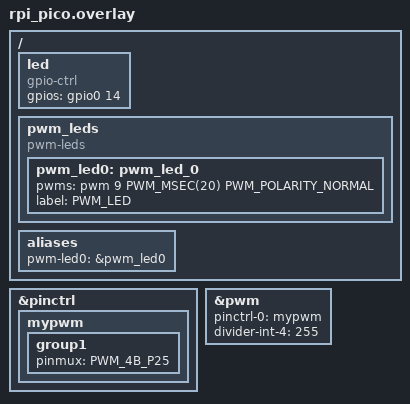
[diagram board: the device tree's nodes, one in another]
/ {
    led: led {
        compatible = "gpio-ctrl";
        gpios = <&gpio0 14 0x0>;
    };

	pwm_leds {
		compatible = "pwm-leds";
		status = "okay";
		pwm_led0: pwm_led_0 {
			pwms = <&pwm 9 PWM_MSEC(20) PWM_POLARITY_NORMAL>;
			label = "PWM_LED";
		};
	};

	aliases {
		//led0 = &led0;
		pwm-led0 = &pwm_led0;
	};
};

&pinctrl {
	mypwm: mypwm {
		group1 {
			pinmux = <PWM_4B_P25>;
		};
	};
};

&pwm {
	pinctrl-0 = <&mypwm>;
	status = "okay";
	divider-int-4 = <255>;
};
